# HDSC_HC32F165 register map
Vendor: HDSC; Series: ARMCM0P; File version: 1.0
CPU: CM0P r0p1, little endian, MPU, FPU, 4 interrupt priority bits
Registers are 32-bit, read-write, reset 0x0 unless marked. A register's access mark holds for its fields unless they carry their own. Offsets are from the block's base; [hi:lo] are bit positions; {n}, {i} and the like mark numbered series; 'fields as' and 'values as' point back to an identical list.

## GPIO
Base 0x40053800
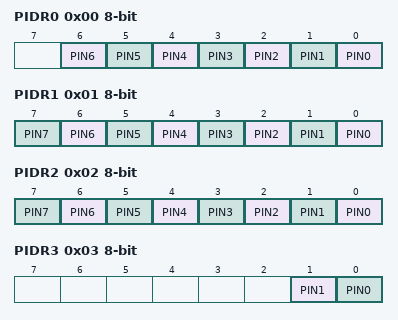
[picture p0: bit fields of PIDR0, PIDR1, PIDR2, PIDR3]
0x00 PIDR0 8-bit ro
  [n] PIN{n} (n=0..6)
0x01 PIDR1 8-bit ro
  [n] PIN{n} (n=0..7)
0x02 PIDR2 8-bit ro
  [n] PIN{n} (n=0..7)
0x03 PIDR3 8-bit ro
  [1] PIN1, [0] PIN0
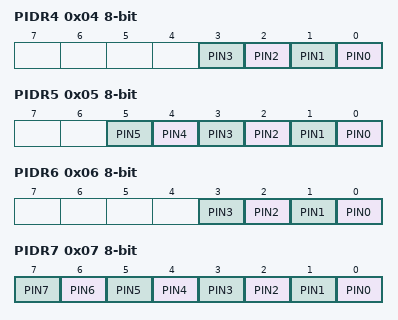
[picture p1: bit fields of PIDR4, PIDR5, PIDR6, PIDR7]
0x04 PIDR4 8-bit ro
  [n] PIN{n} (n=0..3)
0x05 PIDR5 8-bit ro
  [n] PIN{n} (n=0..5)
0x06 PIDR6 8-bit ro
  [n] PIN{n} (n=0..3)
0x07 PIDR7 8-bit ro
  [n] PIN{n} (n=0..7)
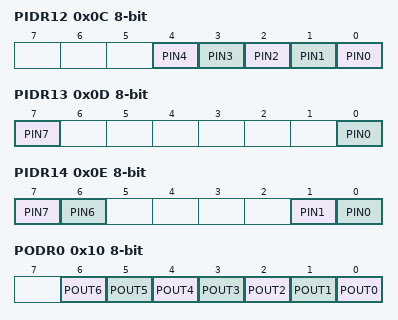
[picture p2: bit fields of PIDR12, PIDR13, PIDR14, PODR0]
0x0C PIDR12 8-bit ro
  [n] PIN{n} (n=0..4)
0x0D PIDR13 8-bit ro
  [7] PIN7, [0] PIN0
0x0E PIDR14 8-bit ro
  [7] PIN7, [6] PIN6, [1] PIN1, [0] PIN0
0x10 PODR0 8-bit
  [n] POUT{n} (n=0..6)
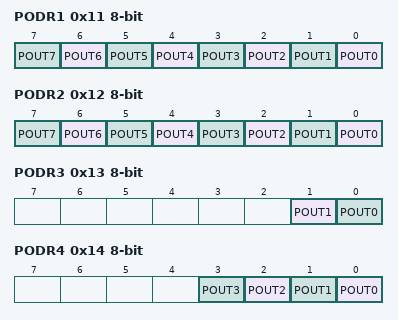
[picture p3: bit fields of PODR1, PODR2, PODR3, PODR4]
0x11 PODR1 8-bit
  [n] POUT{n} (n=0..7)
0x12 PODR2 8-bit
  [n] POUT{n} (n=0..7)
0x13 PODR3 8-bit
  [1] POUT1, [0] POUT0
0x14 PODR4 8-bit
  [n] POUT{n} (n=0..3)
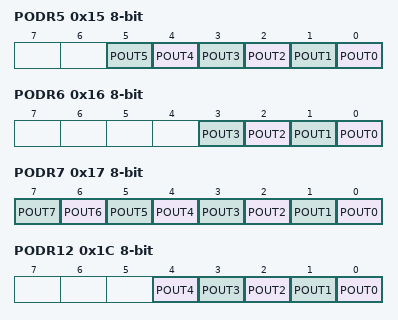
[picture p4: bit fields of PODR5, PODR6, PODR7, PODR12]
0x15 PODR5 8-bit
  [n] POUT{n} (n=0..5)
0x16 PODR6 8-bit
  [n] POUT{n} (n=0..3)
0x17 PODR7 8-bit
  [n] POUT{n} (n=0..7)
0x1C PODR12 8-bit
  [n] POUT{n} (n=0..4)
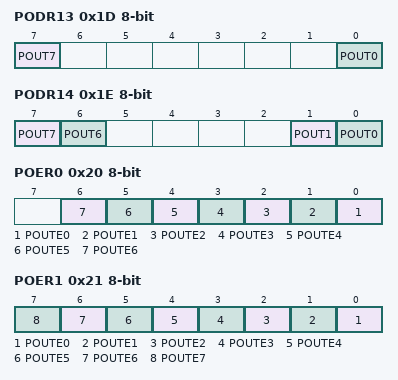
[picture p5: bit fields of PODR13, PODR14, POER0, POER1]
0x1D PODR13 8-bit
  [7] POUT7, [0] POUT0
0x1E PODR14 8-bit
  [7] POUT7, [6] POUT6, [1] POUT1, [0] POUT0
0x20 POER0 8-bit
  [n] POUTE{n} (n=0..6)
0x21 POER1 8-bit
  [n] POUTE{n} (n=0..7)
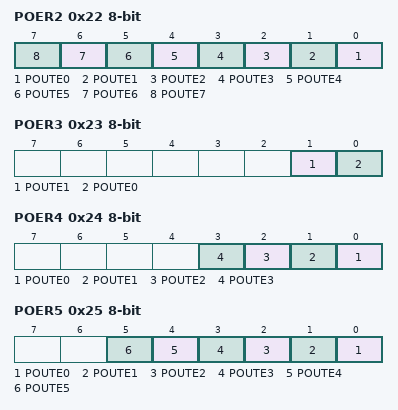
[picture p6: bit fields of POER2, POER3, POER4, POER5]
0x22 POER2 8-bit
  [n] POUTE{n} (n=0..7)
0x23 POER3 8-bit
  [1] POUTE1, [0] POUTE0
0x24 POER4 8-bit
  [n] POUTE{n} (n=0..3)
0x25 POER5 8-bit
  [n] POUTE{n} (n=0..5)
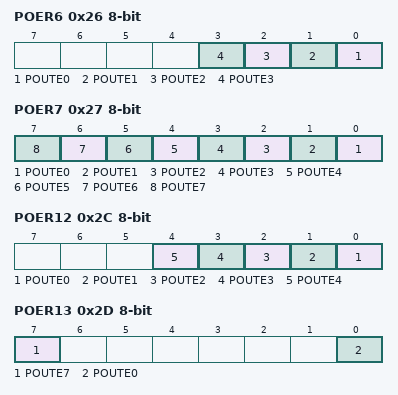
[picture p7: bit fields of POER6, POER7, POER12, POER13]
0x26 POER6 8-bit
  [n] POUTE{n} (n=0..3)
0x27 POER7 8-bit
  [n] POUTE{n} (n=0..7)
0x2C POER12 8-bit
  [n] POUTE{n} (n=0..4)
0x2D POER13 8-bit
  [7] POUTE7, [0] POUTE0
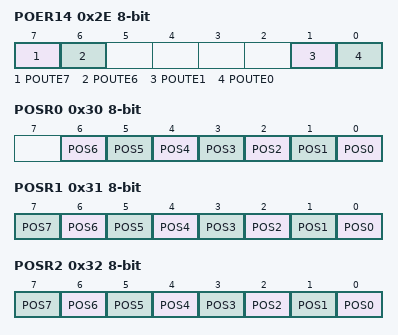
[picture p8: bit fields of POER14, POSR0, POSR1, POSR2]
0x2E POER14 8-bit
  [7] POUTE7, [6] POUTE6, [1] POUTE1, [0] POUTE0
0x30 POSR0 8-bit wo
  [n] POS{n} (n=0..6)
0x31 POSR1 8-bit wo
  [n] POS{n} (n=0..7)
0x32 POSR2 8-bit wo
  [n] POS{n} (n=0..7)
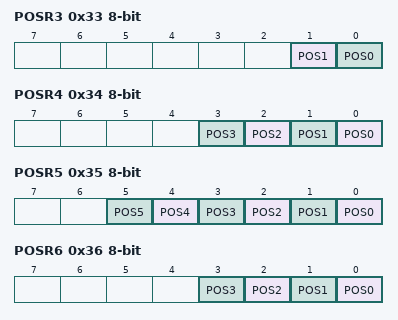
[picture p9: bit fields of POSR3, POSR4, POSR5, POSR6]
0x33 POSR3 8-bit wo
  [1] POS1, [0] POS0
0x34 POSR4 8-bit wo
  [n] POS{n} (n=0..3)
0x35 POSR5 8-bit wo
  [n] POS{n} (n=0..5)
0x36 POSR6 8-bit wo
  [n] POS{n} (n=0..3)
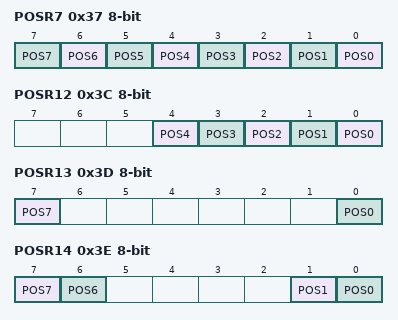
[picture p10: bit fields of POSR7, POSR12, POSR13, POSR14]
0x37 POSR7 8-bit wo
  [n] POS{n} (n=0..7)
0x3C POSR12 8-bit wo
  [n] POS{n} (n=0..4)
0x3D POSR13 8-bit wo
  [7] POS7, [0] POS0
0x3E POSR14 8-bit wo
  [7] POS7, [6] POS6, [1] POS1, [0] POS0
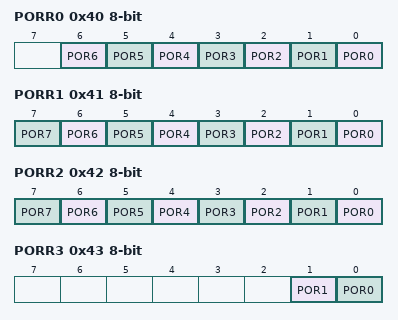
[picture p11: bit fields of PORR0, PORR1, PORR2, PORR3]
0x40 PORR0 8-bit wo
  [n] POR{n} (n=0..6)
0x41 PORR1 8-bit wo
  [n] POR{n} (n=0..7)
0x42 PORR2 8-bit wo
  [n] POR{n} (n=0..7)
0x43 PORR3 8-bit wo
  [1] POR1, [0] POR0
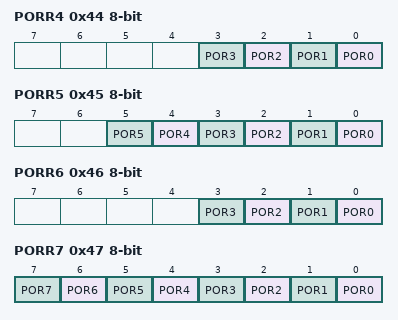
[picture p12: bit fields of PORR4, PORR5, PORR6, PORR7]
0x44 PORR4 8-bit wo
  [n] POR{n} (n=0..3)
0x45 PORR5 8-bit wo
  [n] POR{n} (n=0..5)
0x46 PORR6 8-bit wo
  [n] POR{n} (n=0..3)
0x47 PORR7 8-bit wo
  [n] POR{n} (n=0..7)
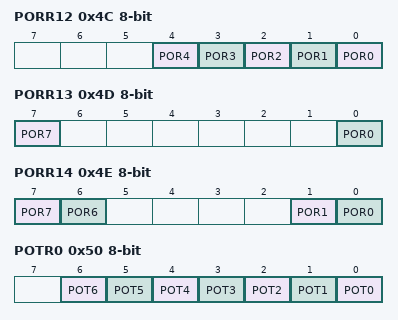
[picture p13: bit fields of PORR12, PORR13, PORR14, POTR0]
0x4C PORR12 8-bit wo
  [n] POR{n} (n=0..4)
0x4D PORR13 8-bit wo
  [7] POR7, [0] POR0
0x4E PORR14 8-bit wo
  [7] POR7, [6] POR6, [1] POR1, [0] POR0
0x50 POTR0 8-bit wo
  [n] POT{n} (n=0..6)
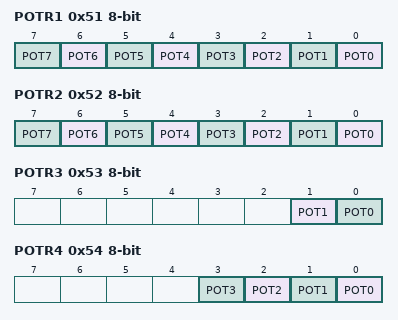
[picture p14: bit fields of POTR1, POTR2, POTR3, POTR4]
0x51 POTR1 8-bit wo
  [n] POT{n} (n=0..7)
0x52 POTR2 8-bit wo
  [n] POT{n} (n=0..7)
0x53 POTR3 8-bit wo
  [1] POT1, [0] POT0
0x54 POTR4 8-bit wo
  [n] POT{n} (n=0..3)
0x55 POTR5 8-bit wo
  [n] POT{n} (n=0..5)
0x56 POTR6 8-bit wo
  [n] POT{n} (n=0..3)
0x57 POTR7 8-bit wo
  [n] POT{n} (n=0..7)
0x5C POTR12 8-bit wo
  [n] POT{n} (n=0..4)
0x5D POTR13 8-bit wo
  [7] POT7, [0] POT0
0x5E POTR14 8-bit wo
  [7] POT7, [6] POT6, [1] POT1, [0] POT0
0x400 PCR00 16-bit
  [14:12] FSEL, [10] CINSEL, [9] INVE, [8] PIN ro, [6] PUU, [5] LTE, [4] DRV, [2] NOD, [1] POUTE, [0] POUT
0x402 PCR01 16-bit
  [15] DDIS, [14:12] FSEL, [11] INTE, [10] CINSEL, [9] INVE, [8] PIN ro, [6] PUU, [5] LTE, [4] DRV, [2] NOD, [1] POUTE, [0] POUT
0x404 PCR02 16-bit
  [15] DDIS, [14:12] FSEL, [10] CINSEL, [9] INVE, [8] PIN ro, [6] PUU, [5] LTE, [4] DRV, [2] NOD, [1] POUTE, [0] POUT
0x406 PCR03 16-bit
  fields as PCR02
0x408 PCR04 16-bit
  fields as PCR00
0x40A PCR05 16-bit
  fields as PCR02
0x40C PCR06 16-bit
  fields as PCR02
0x410 PCR10 16-bit
  fields as PCR02
0x412 PCR11 16-bit
  fields as PCR02
0x414 PCR12 16-bit
  fields as PCR01
{0x3FC+2i} PCR{i} 16-bit (i=13..15)
  fields as PCR02
0x41C PCR16 16-bit
  fields as PCR01
0x41E PCR17 16-bit
  fields as PCR02
{0x3F8+2i} PCR{i} 16-bit (i=20..27)
  fields as PCR01
0x430 PCR30 16-bit
  fields as PCR01
0x432 PCR31 16-bit
  fields as PCR01
0x440 PCR40 16-bit
  fields as PCR00
0x442 PCR41 16-bit
  [14:12] FSEL, [11] INTE, [10] CINSEL, [9] INVE, [8] PIN ro, [6] PUU, [5] LTE, [4] DRV, [2] NOD, [1] POUTE, [0] POUT
0x444 PCR42 16-bit
  fields as PCR00
0x446 PCR43 16-bit
  fields as PCR00
{0x3EC+2i} PCR{i} 16-bit (i=50..53)
  fields as PCR01
0x458 PCR54 16-bit
  fields as PCR02
0x45A PCR55 16-bit
  fields as PCR02
{0x3E8+2i} PCR{i} 16-bit (i=60..63)
  fields as PCR01
{0x3E4+2i} PCR{i} 16-bit (i=70..77)
  fields as PCR01
0x4C0 PCR120 16-bit
  fields as PCR01
{0x3D0+2i} PCR{i} 16-bit (i=121..124)
  fields as PCR02
0x4D0 PCR130 16-bit
  fields as PCR02
0x4DE PCR137 16-bit
  fields as PCR01
0x4E0 PCR140 16-bit
  fields as PCR01
0x4E2 PCR141 16-bit
  fields as PCR41
0x4EC PCR146 16-bit
  fields as PCR01
0x4EE PCR147 16-bit
  fields as PCR01
0x500 PSPCR 16-bit reset 0x3
  [1:0] SPFE
0x504 PCCR 16-bit reset 0x4000
  [15:14] RDWT
0x506 PINAER 16-bit
  [14] PINAE14, [13] PINAE13, [12] PINAE12, [n] PINAE{n} (n=0..7)
0x508 PWPR 16-bit
  [15:8] WP wo, [0] WE
